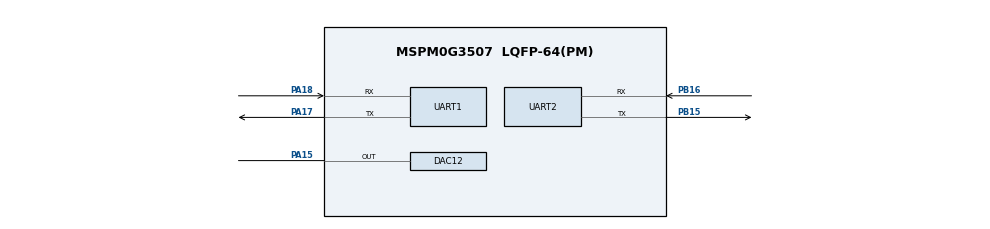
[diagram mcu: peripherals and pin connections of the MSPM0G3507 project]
/**
 * These arguments were used when this file was generated. They will be automatically applied on subsequent loads
 * via the GUI or CLI. Run CLI with '--help' for additional information on how to override these arguments.
 * @cliArgs --device "MSPM0G350X" --part "Default" --package "LQFP-64(PM)" --product "mspm0_sdk@2.04.00.06"
 * @v2CliArgs --device "MSPM0G3507" --package "LQFP-64(PM)" --product "mspm0_sdk@2.04.00.06"
 * @versions {"tool":"1.23.0+4000"}
 */

/**
 * Import the modules used in this configuration.
 */
const ADC12         = scripting.addModule("/ti/driverlib/ADC12", {}, false);
const ADC121        = ADC12.addInstance();
const ADC122        = ADC12.addInstance();
const DAC12         = scripting.addModule("/ti/driverlib/DAC12");
const SYSCTL        = scripting.addModule("/ti/driverlib/SYSCTL");
const TIMER         = scripting.addModule("/ti/driverlib/TIMER", {}, false);
const TIMER1        = TIMER.addInstance();
const TIMER2        = TIMER.addInstance();
const TIMER3        = TIMER.addInstance();
const UART          = scripting.addModule("/ti/driverlib/UART", {}, false);
const UART1         = UART.addInstance();
const UART2         = UART.addInstance();
const ProjectConfig = scripting.addModule("/ti/project_config/ProjectConfig");

/**
 * Write custom configuration values to the imported modules.
 */
ADC121.$name                          = "ADC12_0";
ADC121.repeatMode                     = true;
ADC121.powerDownMode                  = "DL_ADC12_POWER_DOWN_MODE_MANUAL";
ADC121.sampleTime0                    = "62.5ns";
ADC121.configureDMA                   = true;
ADC121.configWinCompLowThld           = 1400;
ADC121.configWinCompHighThld          = 1100;
ADC121.enabledInterrupts              = ["DL_ADC12_INTERRUPT_DMA_DONE","DL_ADC12_INTERRUPT_WINDOW_COMP_HIGH","DL_ADC12_INTERRUPT_WINDOW_COMP_LOW"];
ADC121.adcMem0chansel                 = "DL_ADC12_INPUT_CHAN_2";
ADC121.sampCnt                        = 1;
ADC121.enabledDMATriggers             = ["DL_ADC12_DMA_MEM0_RESULT_LOADED"];
ADC121.adcMem0trig                    = "DL_ADC12_TRIGGER_MODE_TRIGGER_NEXT";
ADC121.trigSrc                        = "DL_ADC12_TRIG_SRC_EVENT";
ADC121.subChanID                      = 3;
ADC121.DMA_CHANNEL.$name              = "DMA_CH0";
ADC121.DMA_CHANNEL.addressMode        = "f2b";
ADC121.DMA_CHANNEL.transferSize       = 1024;
ADC121.DMA_CHANNEL.earlyIntThresh     = "HALF";
ADC121.DMA_CHANNEL.srcLength          = "HALF_WORD";
ADC121.DMA_CHANNEL.dstLength          = "HALF_WORD";
ADC121.DMA_CHANNEL.peripheral.$assign = "DMA_CH0";
ADC121.peripheral.$assign             = "ADC0";
ADC121.adcPin2Config.$name            = "ti_driverlib_gpio_GPIOPinGeneric0";

ADC122.$name                          = "ADC12_1";
ADC122.repeatMode                     = true;
ADC122.powerDownMode                  = "DL_ADC12_POWER_DOWN_MODE_MANUAL";
ADC122.sampleTime0                    = "62.5ns";
ADC122.configureDMA                   = true;
ADC122.sampCnt                        = 1;
ADC122.enabledDMATriggers             = ["DL_ADC12_DMA_MEM0_RESULT_LOADED"];
ADC122.adcMem0trig                    = "DL_ADC12_TRIGGER_MODE_TRIGGER_NEXT";
ADC122.trigSrc                        = "DL_ADC12_TRIG_SRC_EVENT";
ADC122.adcMem0chansel                 = "DL_ADC12_INPUT_CHAN_4";
ADC122.adcMem0wincomp                 = true;
ADC122.configWinCompLowThld           = 1100;
ADC122.enabledInterrupts              = ["DL_ADC12_INTERRUPT_DMA_DONE","DL_ADC12_INTERRUPT_WINDOW_COMP_HIGH"];
ADC122.configWinCompHighThld          = 2000;
ADC122.subChanID                      = 2;
ADC122.DMA_CHANNEL.$name              = "DMA_CH1";
ADC122.DMA_CHANNEL.addressMode        = "f2b";
ADC122.DMA_CHANNEL.transferSize       = 1024;
ADC122.DMA_CHANNEL.earlyIntThresh     = "HALF";
ADC122.DMA_CHANNEL.srcLength          = "HALF_WORD";
ADC122.DMA_CHANNEL.dstLength          = "HALF_WORD";
ADC122.DMA_CHANNEL.peripheral.$assign = "DMA_CH1";
ADC122.peripheral.$assign             = "ADC1";
ADC122.peripheral.adcPin4.$assign     = "PB17";
ADC122.adcPin4Config.$name            = "ti_driverlib_gpio_GPIOPinGeneric1";

const Board = scripting.addModule("/ti/driverlib/Board", {}, false);

DAC12.dacFIFOEn                      = true;
DAC12.dacFIFOTrigger                 = "HWTRIG0";
DAC12.dacConfigureDMA                = true;
DAC12.dacSampleTimerEn               = false;
DAC12.dacFIFOThresh                  = "TWO_QTRS_EMPTY";
DAC12.dacOutputPinEn                 = true;
DAC12.dacAmplifier                   = "ON";
DAC12.sub0ChanID                     = 1;
DAC12.DMA_CHANNEL.$name              = "DMA_CH2";
DAC12.DMA_CHANNEL.addressMode        = "b2f";
DAC12.DMA_CHANNEL.srcLength          = "HALF_WORD";
DAC12.DMA_CHANNEL.dstLength          = "HALF_WORD";
DAC12.DMA_CHANNEL.transferMode       = "FULL_CH_REPEAT_SINGLE";
DAC12.DMA_CHANNEL.peripheral.$assign = "DMA_CH2";
DAC12.peripheral.$assign             = "DAC0";
DAC12.peripheral.OutPin.$assign      = "PA15";
DAC12.OutPinConfig.$name             = "ti_driverlib_gpio_GPIOPinGeneric2";

SYSCTL.forceDefaultClkConfig = true;
SYSCTL.MFPCLKEn              = true;

TIMER1.$name                       = "TIMER_0";
TIMER1.timerMode                   = "PERIODIC";
TIMER1.event1ControllerInterruptEn = ["ZERO_EVENT"];
TIMER1.event2ControllerInterruptEn = ["ZERO_EVENT"];
TIMER1.timerPeriod                 = "1us";
TIMER1.event1PublisherChannel      = 2;

TIMER2.$name                       = "TIMER_1";
TIMER2.timerMode                   = "PERIODIC";
TIMER2.event1PublisherChannel      = 1;
TIMER2.timerStartTimer             = true;
TIMER2.event1ControllerInterruptEn = ["ZERO_EVENT"];
TIMER2.timerPeriod                 = "1us";

TIMER3.$name                       = "TIMER_2";
TIMER3.timerMode                   = "PERIODIC";
TIMER3.timerPeriod                 = "1us";
TIMER3.event1PublisherChannel      = 3;
TIMER3.event1ControllerInterruptEn = ["ZERO_EVENT"];

UART1.$name                            = "UART_1";
UART1.enableFIFO                       = true;
UART1.rxFifoThreshold                  = "DL_UART_RX_FIFO_LEVEL_ONE_ENTRY";
UART1.peripheral.$assign               = "UART1";
UART1.peripheral.rxPin.$assign         = "PA18";
UART1.peripheral.txPin.$assign         = "PA17";
UART1.txPinConfig.direction            = scripting.forceWrite("OUTPUT");
UART1.txPinConfig.hideOutputInversion  = scripting.forceWrite(false);
UART1.txPinConfig.onlyInternalResistor = scripting.forceWrite(false);
UART1.txPinConfig.passedPeripheralType = scripting.forceWrite("Digital");
UART1.txPinConfig.$name                = "ti_driverlib_gpio_GPIOPinGeneric3";
UART1.rxPinConfig.hideOutputInversion  = scripting.forceWrite(false);
UART1.rxPinConfig.onlyInternalResistor = scripting.forceWrite(false);
UART1.rxPinConfig.passedPeripheralType = scripting.forceWrite("Digital");
UART1.rxPinConfig.$name                = "ti_driverlib_gpio_GPIOPinGeneric4";

UART2.$name                            = "UART_2";
UART2.enableFIFO                       = true;
UART2.rxFifoThreshold                  = "DL_UART_RX_FIFO_LEVEL_ONE_ENTRY";
UART2.targetBaudRate                   = 115200;
UART2.peripheral.$assign               = "UART2";
UART2.peripheral.rxPin.$assign         = "PB16";
UART2.peripheral.txPin.$assign         = "PB15";
UART2.txPinConfig.direction            = scripting.forceWrite("OUTPUT");
UART2.txPinConfig.hideOutputInversion  = scripting.forceWrite(false);
UART2.txPinConfig.onlyInternalResistor = scripting.forceWrite(false);
UART2.txPinConfig.passedPeripheralType = scripting.forceWrite("Digital");
UART2.txPinConfig.$name                = "ti_driverlib_gpio_GPIOPinGeneric5";
UART2.rxPinConfig.hideOutputInversion  = scripting.forceWrite(false);
UART2.rxPinConfig.onlyInternalResistor = scripting.forceWrite(false);
UART2.rxPinConfig.passedPeripheralType = scripting.forceWrite("Digital");
UART2.rxPinConfig.$name                = "ti_driverlib_gpio_GPIOPinGeneric6";

ProjectConfig.genLibCMSIS = true;

/**
 * Pinmux solution for unlocked pins/peripherals. This ensures that minor changes to the automatic solver in a future
 * version of the tool will not impact the pinmux you originally saw.  These lines can be completely deleted in order to
 * re-solve from scratch.
 */
ADC121.peripheral.adcPin2.$suggestSolution = "PA25";
Board.peripheral.$suggestSolution          = "DEBUGSS";
Board.peripheral.swclkPin.$suggestSolution = "PA20";
Board.peripheral.swdioPin.$suggestSolution = "PA19";
SYSCTL.peripheral.$suggestSolution         = "SYSCTL";
TIMER1.peripheral.$suggestSolution         = "TIMG0";
TIMER2.peripheral.$suggestSolution         = "TIMA1";
TIMER3.peripheral.$suggestSolution         = "TIMA0";
